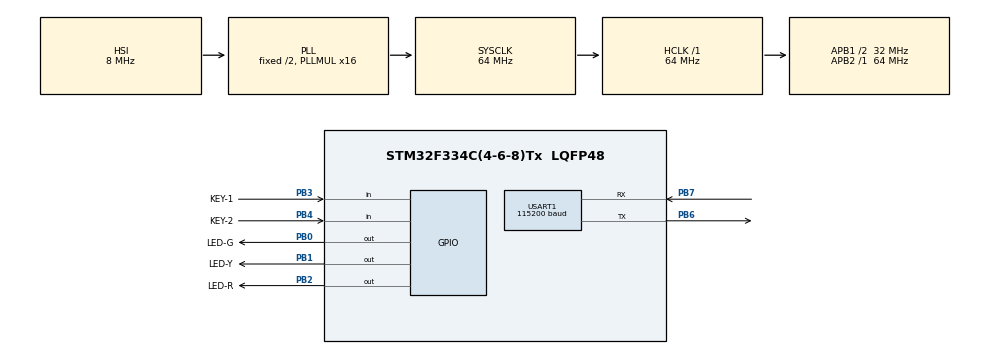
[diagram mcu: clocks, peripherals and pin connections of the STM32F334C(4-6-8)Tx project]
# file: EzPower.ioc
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Mcu.Family=STM32F3
Mcu.Name=STM32F334C(4-6-8)Tx
Mcu.Package=LQFP48
NVIC.PriorityGroup=NVIC_PRIORITYGROUP_4
NVIC.USART1_IRQn=true\:2\:0\:true\:false\:true\:true\:true\:true
PB0.GPIO_Label=LED-G
PB0.GPIO_PuPd=GPIO_PULLUP
PB0.GPIO_Speed=GPIO_SPEED_FREQ_HIGH
PB0.Signal=GPIO_Output
PB1.GPIO_Label=LED-Y
PB1.GPIO_PuPd=GPIO_PULLUP
PB1.GPIO_Speed=GPIO_SPEED_FREQ_HIGH
PB1.Signal=GPIO_Output
PB2.GPIO_Label=LED-R
PB2.GPIO_PuPd=GPIO_PULLUP
PB2.GPIO_Speed=GPIO_SPEED_FREQ_HIGH
PB2.Signal=GPIO_Output
PB3.GPIO_Label=KEY-1
PB3.GPIO_PuPd=GPIO_PULLUP
PB3.Signal=GPIO_Input
PB4.GPIO_Label=KEY-2
PB4.GPIO_PuPd=GPIO_PULLUP
PB4.Signal=GPIO_Input
PB6.Mode=Asynchronous
PB6.Signal=USART1_TX
PB7.Mode=Asynchronous
PB7.Signal=USART1_RX
ProjectManager.HeapSize=0x200
ProjectManager.StackSize=0x400
ProjectManager.TargetToolchain=MDK-ARM V5.32
RCC.AHBFreq_Value=64000000
RCC.APB1CLKDivider=RCC_HCLK_DIV2
RCC.APB1Freq_Value=32000000
RCC.APB1TimFreq_Value=64000000
RCC.APB2Freq_Value=64000000
RCC.APB2TimFreq_Value=64000000
RCC.CortexFreq_Value=64000000
RCC.HCLKFreq_Value=64000000
RCC.HRTIMSelection=RCC_HRTIM1CLK_PLLCLK
RCC.HSE_VALUE=8000000
RCC.HSI_VALUE=8000000
RCC.LSE_VALUE=32768
RCC.PLLMUL=RCC_PLL_MUL16
RCC.SYSCLKFreq_VALUE=64000000
RCC.SYSCLKSourceVirtual=RCC_SYSCLKSOURCE_PLLCLK
TIM3.Period=10000
TIM3.Prescaler=32
USART1.BaudRate=115200
USART1.VirtualMode-Asynchronous=VM_ASYNC
VP_TIM3_VS_ClockSourceINT.Mode=Internal
VP_TIM3_VS_ClockSourceITR.Mode=TriggerSource_ITR0
board=custom

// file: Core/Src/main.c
/* USER CODE BEGIN Header */
/**
  ******************************************************************************
  * @file           : main.c
  * @brief          : Main program body
  ******************************************************************************
  * @attention
  *
  * Copyright (c) 2022 STMicroelectronics.
  * All rights reserved.
  *
  * This software is licensed under terms that can be found in the LICENSE file
  * in the root directory of this software component.
  * If no LICENSE file comes with this software, it is provided AS-IS.
  *
  ******************************************************************************
  */
/* USER CODE END Header */
#include "main.h"
#include "tim.h"
#include "usart.h"
#include "gpio.h"

/* USER CODE BEGIN Includes */
#include "datatran.h"
/* USER CODE END Includes */

void SystemClock_Config(void);

int main(void)
{

  /* MCU Configuration--------------------------------------------------------*/

  /* Reset of all peripherals, Initializes the Flash interface and the Systick. */
  HAL_Init();

  /* Configure the system clock */
  SystemClock_Config();

  /* Initialize all configured peripherals */
  MX_GPIO_Init();
  MX_TIM3_Init();
  MX_USART1_UART_Init();
  /* USER CODE BEGIN 2 */
		HAL_UART_Receive_IT(&huart1, (uint8_t *)aRXBuffer, RXBUFFERSIZE);
		uint8_t len = 0;
		uint16_t Cnt = 0;
		printf("Hello, i am %s\n", "mculover666");
		printf("I'm working");
  /* USER CODE END 2 */

  /* Infinite loop */
  while (1)
  {
		//if(USART_RX_STA&0x8000)
		//{
			Cnt ++;
			if(Cnt == 0xFFFF)
			{
				Cnt = 0;
				len=USART_RX_STA&0x3fff;//得到此次接收到的数据长度
				if(len!=0)
					printf("The things you gave me:\n");
				HAL_UART_Transmit(&huart1,(uint8_t*)USART_RX_BUF,len,1000);	//发送接收到的数据
				while(__HAL_UART_GET_FLAG(&huart1,UART_FLAG_TC)!=SET);		//等待发送结束
				USART_RX_STA=0;
			}
		//}
  }
}

void SystemClock_Config(void)
{
  RCC_OscInitTypeDef RCC_OscInitStruct = {0};
  RCC_ClkInitTypeDef RCC_ClkInitStruct = {0};
  RCC_PeriphCLKInitTypeDef PeriphClkInit = {0};

  /** Initializes the RCC Oscillators according to the specified parameters
  * in the RCC_OscInitTypeDef structure.
  */
  RCC_OscInitStruct.OscillatorType = RCC_OSCILLATORTYPE_HSI;
  RCC_OscInitStruct.HSIState = RCC_HSI_ON;
  RCC_OscInitStruct.HSICalibrationValue = RCC_HSICALIBRATION_DEFAULT;
  RCC_OscInitStruct.PLL.PLLState = RCC_PLL_ON;
  RCC_OscInitStruct.PLL.PLLSource = RCC_PLLSOURCE_HSI;
  RCC_OscInitStruct.PLL.PLLMUL = RCC_PLL_MUL16;
  if (HAL_RCC_OscConfig(&RCC_OscInitStruct) != HAL_OK)
  {
    Error_Handler();
  }

  /** Initializes the CPU, AHB and APB buses clocks
  */
  RCC_ClkInitStruct.ClockType = RCC_CLOCKTYPE_HCLK|RCC_CLOCKTYPE_SYSCLK
                              |RCC_CLOCKTYPE_PCLK1|RCC_CLOCKTYPE_PCLK2;
  RCC_ClkInitStruct.SYSCLKSource = RCC_SYSCLKSOURCE_PLLCLK;
  RCC_ClkInitStruct.AHBCLKDivider = RCC_SYSCLK_DIV1;
  RCC_ClkInitStruct.APB1CLKDivider = RCC_HCLK_DIV2;
  RCC_ClkInitStruct.APB2CLKDivider = RCC_HCLK_DIV1;

  if (HAL_RCC_ClockConfig(&RCC_ClkInitStruct, FLASH_LATENCY_2) != HAL_OK)
  {
    Error_Handler();
  }
  PeriphClkInit.PeriphClockSelection = RCC_PERIPHCLK_USART1;
  PeriphClkInit.Usart1ClockSelection = RCC_USART1CLKSOURCE_PCLK1;
  if (HAL_RCCEx_PeriphCLKConfig(&PeriphClkInit) != HAL_OK)
  {
    Error_Handler();
  }
}

void Error_Handler(void)
{
  __disable_irq();
  while (1)
  {
  }
}
